# VPAC0_PAR_VPAC_LDC0_S_VBUSP_MMR_VBUSP register map
Vendor: Texas Instruments
Peripheral module from a debugger description file (folder J7ES).
Registers are 32-bit, read-write, reset 0x0 unless marked. A register's access mark holds for its fields unless they carry their own. Offsets are as the file gives them; lines under a group give offsets from that group; [hi:lo] are bit positions; {n}, {i} and the like mark numbered series; 'fields as' and 'values as' point back to an identical list; <NAME> marks a mode.

## VPAC0_PAR_VPAC_LDC0_S_VBUSP_MMR_VBUSP
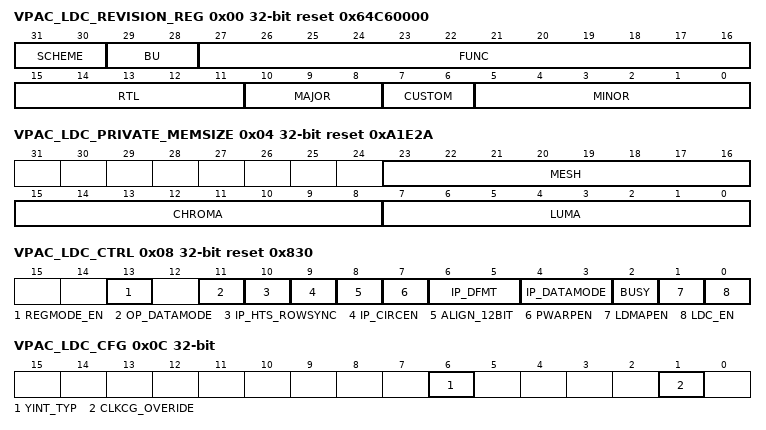
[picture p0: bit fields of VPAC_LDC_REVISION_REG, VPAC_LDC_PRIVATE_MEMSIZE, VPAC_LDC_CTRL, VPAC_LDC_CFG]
0x00 VPAC_LDC_REVISION_REG ro reset 0x64C60000 — LDC PID
  [31:30] SCHEME — Used to distinguish between old scheme and new scheme.
  [29:28] BU — BU indicator DSPS ==&gt; 0x0 WTBU ==&gt; 0x1 Processors ==&gt; 0x2
  [27:16] FUNC — Function indicates a software compatible module family.
  [15:11] RTL — RTL Version.
  [10:8] MAJOR — Major Revision.
  [7:6] CUSTOM — Indicates a special version for a particular device.
  [5:0] MINOR — Minor Revision.
0x04 VPAC_LDC_PRIVATE_MEMSIZE ro reset 0xA1E2A — Memory size mentioned is for both ping and pong combined. Error interrupts are generated based on the memory size available.
  [23:16] MESH — Mesh Private pixel memory size in KBytes
  [15:8] CHROMA — Chroma Private pixel memory size in KBytes
  [7:0] LUMA — Luma Private pixel memory size in KBytes
0x08 VPAC_LDC_CTRL access not given reset 0x830 — Control Register to Enable/Disable and select modes of operation
  [13] REGMODE_EN rw — Enables for Frame division into multiple regions.
  [11] OP_DATAMODE rw — Output Pixel Data Mode
  [10] IP_HTS_ROWSYNC rw — Enables control of Input Fetch with HTS at Block Row level.
  [9] IP_CIRCEN rw — Enables circular addressing mode on input pixel fetch.
  [8] ALIGN_12BIT rw — Alignment of
  [7] PWARPEN rw — Perspective warp transform Enable.
  [6:5] IP_DFMT rw — Input Pixel Data Format
  [4:3] IP_DATAMODE rw — Input Pixel Data Mode
  [2] BUSY ro — Idle/Busy Status,
  [1] LDMAPEN rw — Distortion Back Mapping Enable.
  [0] LDC_EN — Write 1 to Start LDC function. (access RW1S)
0x0C VPAC_LDC_CFG — LDC Configuration register. YINT_TYP parameter is used The YINT_TYP parameter only applies to the Y component (Luma). If YINT_TYP = 0, Y pixels are processed using bicubic interpolation, which requires 2 cycles per pixel to process. If YINT_TYP = 1, Y pixels are processed using bilinear interpolation, which requires 1 cycle per pixel to process. This allows a tradeoff between performance versus quality. CbCr (Chroma) pixels are always processed using bilinear interpolation. Thus, the overall performance of pixel processing is based on the Y interpolation type setting.
  [6] YINT_TYP — Interpolation type for Y data.
  [1] CLKCG_OVERIDE — Override power saving clock gating inserted by design.
0x10 VPAC_LDC_MESHTABLE_CFG — Defines the down-sampling factors used for the mesh offset tables
  [2:0] M — Mesh table down-sampling factor (by 2
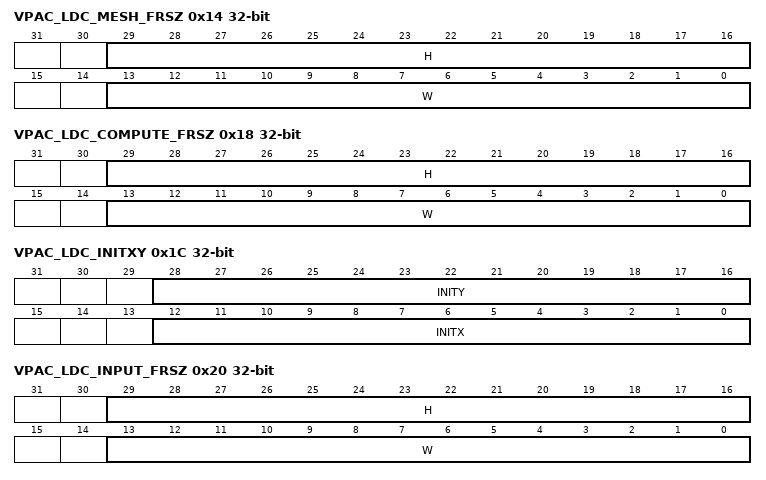
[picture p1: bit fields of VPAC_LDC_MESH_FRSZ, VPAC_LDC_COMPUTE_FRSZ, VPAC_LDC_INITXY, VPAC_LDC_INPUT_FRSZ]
0x14 VPAC_LDC_MESH_FRSZ — Mesh data mapping is available for this Frame size. Actual number of mesh data entires depend Mesh Frame size and Mesh sampling factor. This Frame size is independent from
  [29:16] H — Mesh Frame height in Lines
  [13:0] W — Mesh Frame Width
0x18 VPAC_LDC_COMPUTE_FRSZ — H corresponds to the total number of lines to process. W corresponds to the number of pixels to process in each line. This parameters must be loaded as actual pixel counts, NOT pixel counts - 1. W and H must both be less than or equal to 8192. The hardware does not support output coordinates larger than 8192. Therefore, .W + .INITX must be no larger than 8192. Also .H + .INITY must be no larger than 8192.
  [29:16] H — Output Frame height in Lines.
  [13:0] W — Output Frame Width.
0x1C VPAC_LDC_INITXY — LDC Initial Output Co-ordinate to process
  [28:16] INITY — Output starting Y-coordinate.
  [12:0] INITX — Output starting X-coordinate.
0x20 VPAC_LDC_INPUT_FRSZ — Defines the total input frame size
  [29:16] H — Input Frame height in Lines.
  [13:0] W — Input Frame Width in Pixels.
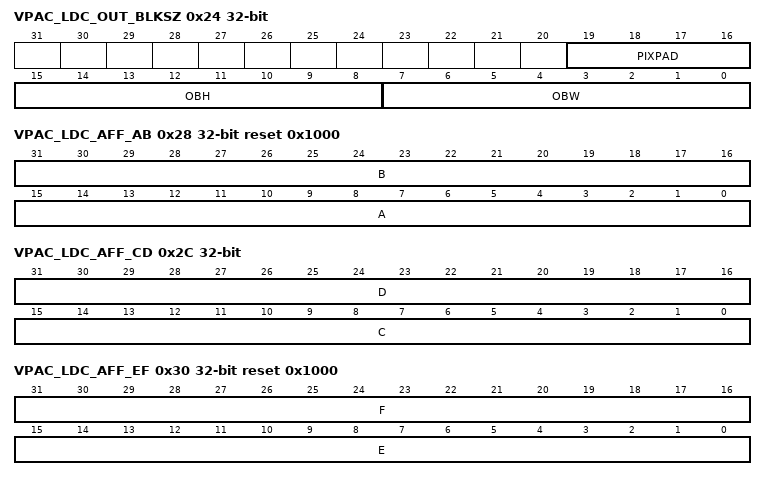
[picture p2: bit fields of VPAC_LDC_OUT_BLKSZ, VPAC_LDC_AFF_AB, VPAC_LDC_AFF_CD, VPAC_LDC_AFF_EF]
0x24 VPAC_LDC_OUT_BLKSZ — LDC Output Block parameter registers. These parameters represent actual pixel counts, NOT pixel counts - 1. OBW must be greater than 0 and less than or equal to frame width (.W). OBH must be greater than 0 and less than or equal to frame height (.H).
  [19:16] PIXPAD — Pixel pad
  [15:8] OBH — Output block height must be &gt;0 and even
  [7:0] OBW — Output block width, must be &gt;0 and multiple of 8
0x28 VPAC_LDC_AFF_AB reset 0x1000 — LDC Affine Transwarp A/B
  [31:16] B — Affine transwarp B (S16Q12)
  [15:0] A — Affine transwarp A (S16Q12)
0x2C VPAC_LDC_AFF_CD — LDC Affine Transwarp C/D
  [31:16] D — Affine transwarp D (S16Q12)
  [15:0] C — Affine transwarp C (S16Q3)
0x30 VPAC_LDC_AFF_EF reset 0x1000 — LDC Affine Transwarp E/F
  [31:16] F — Affine transwarp F (S16Q3)
  [15:0] E — Affine transwarp E (S16Q12)
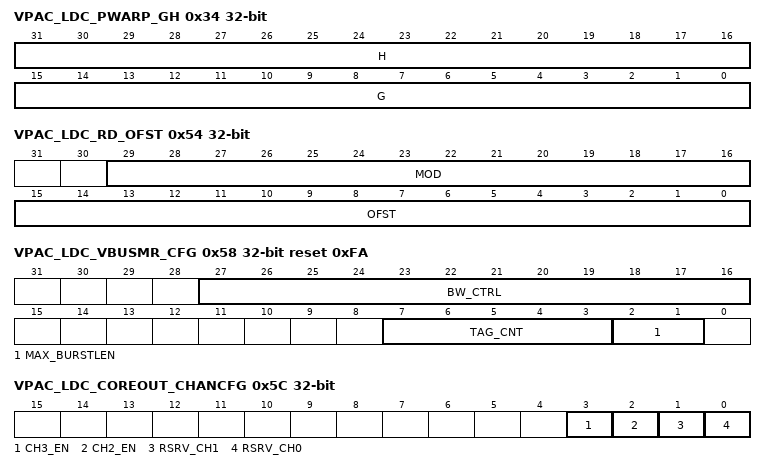
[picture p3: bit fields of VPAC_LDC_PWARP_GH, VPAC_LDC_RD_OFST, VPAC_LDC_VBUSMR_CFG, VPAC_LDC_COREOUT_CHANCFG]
0x34 VPAC_LDC_PWARP_GH — LDC Perspective Transformation Parameters, G and H
  [31:16] H — Perspective Transformation H (S16Q23)
  [15:0] G — Perspective Transformation H (S16Q23)
0x38 VPAC_LDC_MESH_BASE_H — Higher 16-bit of Mesh Table Base Address
  [15:0] ADDR — Higher
0x3C VPAC_LDC_MESH_BASE_l — Lower 32-bit of Mesh Table Base Address
  [31:0] ADDR — Lower 32-bit of Read Base address for mesh offset table.
0x40 VPAC_LDC_MESH_OFST — Defines the stride between rows for the Mesh table in bytes.
  [15:0] OFST — LDC Mesh table line offset, must be
0x44 VPAC_LDC_RD_BASE_H — Higher 16-bit of Input Frame Base Address
  [15:0] ADDR — Higher
0x48 VPAC_LDC_RD_BASE_l — Lower 32-bit of Input Frame Base Address
  [31:0] ADDR — Lower 32-bit of Read Base address of Input Frame Base Address.
0x4C VPAC_LDC_RD_420C_BASE_H — Higher 16-bit of Input Frame 420C Base Address
  [15:0] ADDR — Higher
0x50 VPAC_LDC_RD_420C_BASE_l — Lower 32-bit of Input Frame Chroma Base Address in YUV420
  [31:0] ADDR — Lower 32-bit of Read Base address of Input Frame Chroma Base Address in YUV420.
0x54 VPAC_LDC_RD_OFST — Defines the stride between rows for the Input Frame in bytes.
  [29:16] MOD — Sets the circular buffer size if circular buffering mode is used.
  [15:0] OFST — Read frame line offset, must be
0x58 VPAC_LDC_VBUSMR_CFG reset 0xFA — Control VBUSM Read Interface
  [27:16] BW_CTRL — Limits the mean bandwidth (computed over one block) that the LDC module can request for read from system memory.
  [7:3] TAG_CNT — Limits the maximum number of outstanding LDC requests to TAG_CNT+1
  [2:1] MAX_BURSTLEN — Limits the maximum burst length that could be used by LDC.
0x5C VPAC_LDC_COREOUT_CHANCFG access per field — LDC Core to LSE output channel enable control
  [3] CH3_EN rw — Enable for LDC Core to LSE Channel_3 connection used for Chroma Dual output
  [2] CH2_EN rw — Enable for LDC Core to LSE Channel_2 connection used for Luma Dual output
  [1] RSRV_CH1 ro — Primary Chroma channel (LSE Channel_1) enable extracted from output data mode
  [0] RSRV_CH0 ro — Primary Luuma channel (LSE Channel_0) enable extracted from output data mode
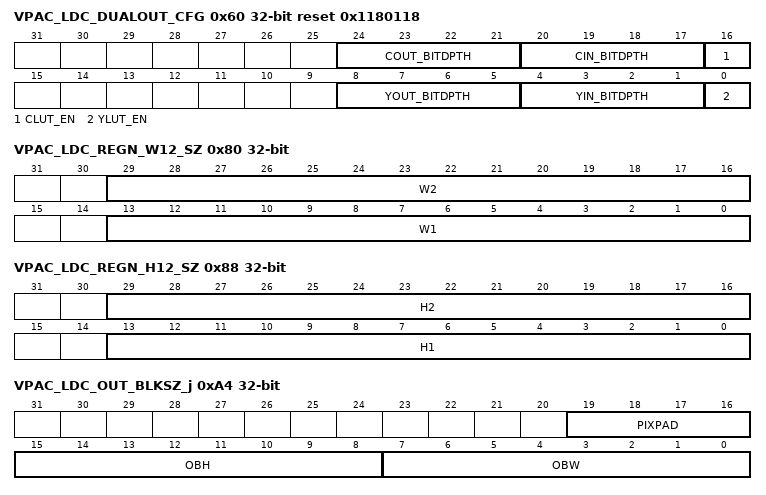
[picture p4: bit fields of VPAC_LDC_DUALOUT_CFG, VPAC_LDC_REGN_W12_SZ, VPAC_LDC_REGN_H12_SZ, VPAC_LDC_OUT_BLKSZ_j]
0x60 VPAC_LDC_DUALOUT_CFG reset 0x1180118 — Configuration for Dual Luma and Chroma channels and LUT
  [24:21] COUT_BITDPTH — Chroma Output Data Bit depth.
  [20:17] CIN_BITDPTH — Chroma Input Data Bit depth.
  [16] CLUT_EN — Chroma LUT mapping enable.
  [8:5] YOUT_BITDPTH — Luma Output Data Bit depth.
  [4:1] YIN_BITDPTH — Luma Input Data Bit depth.
  [0] YLUT_EN — Luma LUT mapping enable.
0x80 VPAC_LDC_REGN_W12_SZ — Horizontal slice width for Region division
  [29:16] W2 — Width of second horizontal slice.
  [13:0] W1 — Width of first horizontal slice.
0x84 VPAC_LDC_REGN_W3_SZ — Horizontal slice width for Region division
  [13:0] W3 — Width of third horizontal slice.
0x88 VPAC_LDC_REGN_H12_SZ — vertical slice height for Region division
  [29:16] H2 — Height of second vertical slice.
  [13:0] H1 — Height of first vertical slice.
0x8C VPAC_LDC_REGN_H3_SZ — vertical slice height for Region division
  [13:0] H3 — Height of third vertical slice.
0xA0 VPAC_LDC_CTRL_j reset 0x1 — Region Control Register Offset = 000200A0h + (j * 8h); where j = 0h to 8h
  [0] ENABLE — Enable for processing of this region.
0xA4 VPAC_LDC_OUT_BLKSZ_j — Block size and Pixel Pad config Offset = 000200A4h + (j * 8h); where j = 0h to 8h
  [19:16] PIXPAD — Pixel pad
  [15:8] OBH — Output block height must be &gt;0 and even.
  [7:0] OBW — Output block width, must be &gt;0 and multiple of 8.
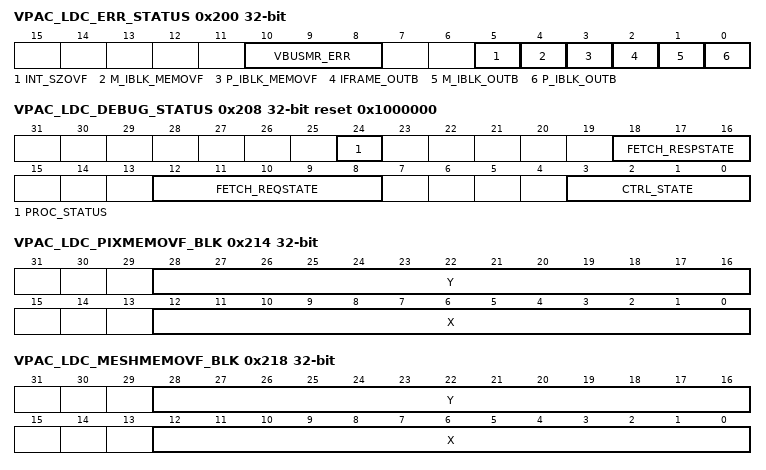
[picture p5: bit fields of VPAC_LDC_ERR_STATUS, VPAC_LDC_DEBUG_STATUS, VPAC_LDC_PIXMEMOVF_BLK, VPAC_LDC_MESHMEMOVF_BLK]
0x200 VPAC_LDC_ERR_STATUS access not given — Control VBUSM Read Interface
  [10:8] VBUSMR_ERR — VBUSM Read I/F Last Error Status. (access RW1C)
  [5] INT_SZOVF — Internal operation has overflown the HW supported block or frame sizes. (access RW1C)
  [4] M_IBLK_MEMOVF — Mesh block storage requirement is more than internal memory available. (access RW1C)
  [3] P_IBLK_MEMOVF — Input pixel block storage requirement is more than internal memory available. (access RW1C)
  [2] IFRAME_OUTB — Either Mesh data or Input pixel data required is going out of valid frame available (access RW1C)
  [1] M_IBLK_OUTB — Mesh Input Block out of Bound. (access RW1C)
  [0] P_IBLK_OUTB — Pixel Input Block out of Bound. (access RW1C)
0x204 VPAC_LDC_DEBUG_CTRL — Control the memory access selection
  [0] CFG_MEMACC_SEL — VBUSP Configuration access control.
0x208 VPAC_LDC_DEBUG_STATUS ro reset 0x1000000 — LDC Debug Status Register
  [24] PROC_STATUS — Block Processing status.
  [18:16] FETCH_RESPSTATE — VBUSM Fetch Response state machine 3'd
  [12:8] FETCH_REQSTATE — VBUSM Fetch Request state machine 5'b00_
  [3:0] CTRL_STATE — Main Control State machine 4'd
0x20C VPAC_LDC_FR_PDFTCH ro — Pixel bytes fetched by VBUSM Read Interface. It is updated on every command issued and cleared at the beginning frame fetch. Reading at the end of the frame will provide total number of pixel data fetched for entire frame
  [31:0] PBYTES — Pixel bytes fetched for current Frame.
0x210 VPAC_LDC_FR_MDFTCH ro — Mesh bytes fetched by VBUSM Read Interface. It is updated on every command issued and cleared at the beginning frame fetch. Reading at the end of the frame will provide total number of mesh data band fetched for entire frame
  [31:0] MBYTES — Mesh bytes fetched for current Frame.
0x214 VPAC_LDC_PIXMEMOVF_BLK ro — Starting co-ordinates of first output block for which input pixel buffer overflowed
  [28:16] Y — Start Y Co-ordinate
  [12:0] X — Start X Co-ordinate
0x218 VPAC_LDC_MESHMEMOVF_BLK ro — Starting co-ordinates of first output block for which input mesh buffer overflowed
  [28:16] Y — Start Y Co-ordinate
  [12:0] X — Start X Co-ordinate
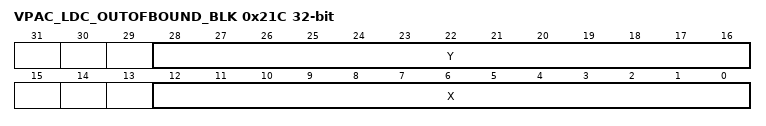
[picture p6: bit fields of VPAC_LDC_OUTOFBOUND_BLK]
0x21C VPAC_LDC_OUTOFBOUND_BLK ro — Starting co-ordinates of first output block for which PIX_PAD is not enough
  [28:16] Y — Start Y Co-ordinate
  [12:0] X — Start X Co-ordinate
